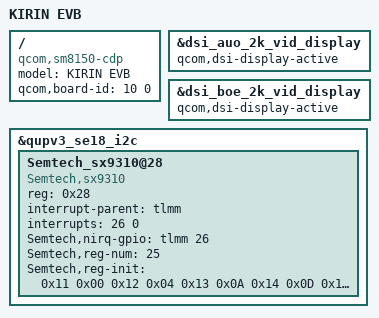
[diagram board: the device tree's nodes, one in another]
/* Copyright (c) 2017-2018, The Linux Foundation. All rights reserved.
 *
 * This program is free software; you can redistribute it and/or modify
 * it under the terms of the GNU General Public License version 2 and
 * only version 2 as published by the Free Software Foundation.
 *
 * This program is distributed in the hope that it will be useful,
 * but WITHOUT ANY WARRANTY; without even the implied warranty of
 * MERCHANTABILITY or FITNESS FOR A PARTICULAR PURPOSE.  See the
 * GNU General Public License for more details.
 */

/dts-v1/;
/plugin/;

#include <dt-bindings/clock/qcom,gcc-sm8150.h>
#include <dt-bindings/clock/qcom,camcc-sm8150.h>
#include <dt-bindings/clock/qcom,rpmh.h>
#include <dt-bindings/interrupt-controller/arm-gic.h>

#include "sm8150-cdp.dtsi"
#include "sm8150-cdp-audio-overlay.dtsi"

/ {
	model = "KIRIN EVB";
	compatible = "qcom,sm8150-cdp", "qcom,sm8150", "qcom,cdp";
	qcom,board-id = <10 0>;
};

//&dsi_sharp_4k_dsc_cmd_display {
	//qcom,dsi-display-active;
//};
&dsi_auo_2k_vid_display {
	qcom,dsi-display-active;
};

&dsi_boe_2k_vid_display {
	qcom,dsi-display-active;
};

&qupv3_se18_i2c {
        status = "ok";
        Semtech_sx9310@28 {
                compatible = "Semtech,sx9310";
                reg = <0x28>;
                interrupt-parent = <&tlmm>;
                interrupts = <26 0>;

                Semtech,nirq-gpio = <&tlmm 26 0x00>;
                Semtech,reg-num = <25>; /*total register number to initialize*/
                Semtech,reg-init  = /bits/ 8 < 0x11 0x00
                                0x12 0x04
                                0x13 0x0A
                                0x14 0x0D
                                0x15 0xC1
                                0x16 0x20
                                0x17 0x4C
                                0x18 0x7E
                                0x19 0x7D
                                0x1A 0x00
                                0x1B 0x00
                                0x1C 0x00
                                0x1D 0x00
                                0x1E 0x00
                                0x1F 0x00
                                0x20 0x00
                                0x21 0x04
                                0x22 0x00
                                0x23 0x00
                                0x2A 0x00
                                0x2B 0x80
                                0x2C 0x0C
                                0x03 0x60
                                0x04 0x00
                                0x10 0x27>;
        };
};

